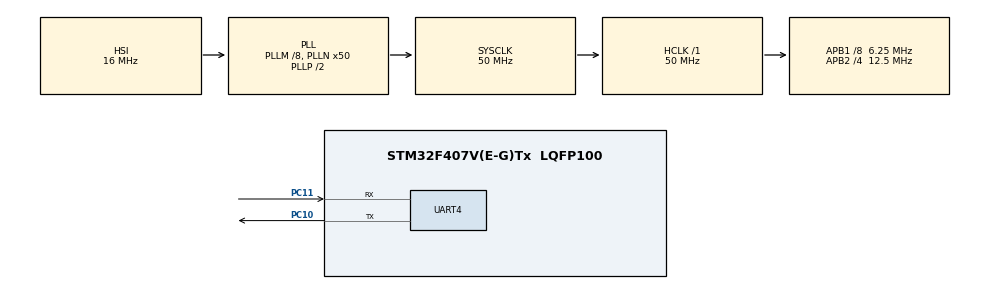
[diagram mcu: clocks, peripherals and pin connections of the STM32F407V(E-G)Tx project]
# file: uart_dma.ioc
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Dma.Request0=UART4_RX
Dma.Request1=UART4_TX
Dma.UART4_RX.0.Direction=DMA_PERIPH_TO_MEMORY
Dma.UART4_RX.0.FIFOMode=DMA_FIFOMODE_DISABLE
Dma.UART4_RX.0.Instance=DMA1_Stream2
Dma.UART4_RX.0.MemDataAlignment=DMA_MDATAALIGN_BYTE
Dma.UART4_RX.0.MemInc=DMA_MINC_ENABLE
Dma.UART4_RX.0.Mode=DMA_CIRCULAR
Dma.UART4_RX.0.PeriphDataAlignment=DMA_PDATAALIGN_BYTE
Dma.UART4_RX.0.PeriphInc=DMA_PINC_DISABLE
Dma.UART4_RX.0.Priority=DMA_PRIORITY_LOW
Dma.UART4_TX.1.Direction=DMA_MEMORY_TO_PERIPH
Dma.UART4_TX.1.FIFOMode=DMA_FIFOMODE_DISABLE
Dma.UART4_TX.1.Instance=DMA1_Stream4
Dma.UART4_TX.1.MemDataAlignment=DMA_MDATAALIGN_BYTE
Dma.UART4_TX.1.MemInc=DMA_MINC_ENABLE
Dma.UART4_TX.1.Mode=DMA_NORMAL
Dma.UART4_TX.1.PeriphDataAlignment=DMA_PDATAALIGN_BYTE
Dma.UART4_TX.1.PeriphInc=DMA_PINC_DISABLE
Dma.UART4_TX.1.Priority=DMA_PRIORITY_LOW
Mcu.Family=STM32F4
Mcu.Name=STM32F407V(E-G)Tx
Mcu.Package=LQFP100
NVIC.DMA1_Stream2_IRQn=true\:0\:0\:false\:false\:true\:false\:true
NVIC.DMA1_Stream4_IRQn=true\:0\:0\:false\:false\:true\:false\:true
NVIC.PriorityGroup=NVIC_PRIORITYGROUP_0
NVIC.UART4_IRQn=true\:0\:0\:false\:false\:true\:true\:true
PC10.Mode=Asynchronous
PC10.Signal=UART4_TX
PC11.Mode=Asynchronous
PC11.Signal=UART4_RX
ProjectManager.HeapSize=0x200
ProjectManager.StackSize=0x400
ProjectManager.TargetToolchain=STM32CubeIDE
RCC.48MHZClocksFreq_Value=14285714.285714285
RCC.AHBFreq_Value=50000000
RCC.APB1CLKDivider=RCC_HCLK_DIV8
RCC.APB1Freq_Value=6250000
RCC.APB1TimFreq_Value=12500000
RCC.APB2CLKDivider=RCC_HCLK_DIV4
RCC.APB2Freq_Value=12500000
RCC.APB2TimFreq_Value=25000000
RCC.CortexFreq_Value=50000000
RCC.HCLKFreq_Value=50000000
RCC.HSE_VALUE=8000000
RCC.HSI_VALUE=16000000
RCC.LSE_VALUE=32768
RCC.PLLM=8
RCC.PLLN=50
RCC.PLLQ=7
RCC.SYSCLKFreq_VALUE=50000000
RCC.SYSCLKSource=RCC_SYSCLKSOURCE_PLLCLK
RCC.VCOOutputFreq_Value=100000000
UART4.VirtualMode=Asynchronous
board=STM32F407G-DISC1

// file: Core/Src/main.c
/* USER CODE BEGIN Header */
/**
  ******************************************************************************
  * @file           : main.c
  * @brief          : Main program body
  ******************************************************************************
  * @attention
  *
  * <h2><center>&copy; Copyright (c) 2020 STMicroelectronics.
  * All rights reserved.</center></h2>
  *
  * This software component is licensed by ST under Ultimate Liberty license
  * SLA0044, the "License"; You may not use this file except in compliance with
  * the License. You may obtain a copy of the License at:
  *                             www.st.com/SLA0044
  *
  ******************************************************************************
  */
/* USER CODE END Header */

#include "main.h"

/* USER CODE BEGIN Includes */
#include <string.h>
#include <stdint.h>
/* USER CODE END Includes */

/* USER CODE BEGIN PD */
struct Buffer
{
    uint8_t front;
    uint8_t rear;
    uint8_t *arr;
};
//struct Buffer buffDMA;
struct Buffer buffUSR;

void buffer_init(struct Buffer *buff, uint8_t *buff_name);
//void buffer_add(struct Buffer *buff, uint8_t data);
//uint8_t buffer_get(struct Buffer *buff);
//uint8_t buffer_space(struct Buffer *buff);

/* USER CODE END PD */

/* USER CODE BEGIN PM */
//Size of buffer - DMA
#define DMA_BUFF_SIZE 10
//Size of buffer - USER
#define USR_BUFF_SIZE 50
/*
//Circular buffer EMPTY condition
#define BUFF_EMPTY  0
//Circular buffer FULL condition
#define BUFF_FULL   1
//Circular buffer NOT FULL condition
#define BUFF_NOT_FULL   2
*/

/* USER CODE END PM */

UART_HandleTypeDef huart4;
DMA_HandleTypeDef hdma_uart4_rx;
DMA_HandleTypeDef hdma_uart4_tx;

/* USER CODE BEGIN PV */
void delay(void);
/* USER CODE END PV */

void SystemClock_Config(void);
static void MX_GPIO_Init(void);
static void MX_DMA_Init(void);
static void MX_UART4_Init(void);

/* USER CODE BEGIN 0 */
uint8_t dma_buf[DMA_BUFF_SIZE];
uint8_t usr_buf[USR_BUFF_SIZE];	//circular buffer
uint8_t status = 0;
uint8_t tx_count = 0;
uint8_t rx_count = 0;

uint8_t temp[2] = {'a', 'b'};
/* USER CODE END 0 */

int main(void)
{

  /* MCU Configuration--------------------------------------------------------*/

  /* Reset of all peripherals, Initializes the Flash interface and the Systick. */
  HAL_Init();

  /* USER CODE BEGIN Init */
  //buffer_init(&buffDMA, dma_buf);
  buffer_init(&buffUSR, usr_buf);
  /* USER CODE END Init */

  /* Configure the system clock */
  SystemClock_Config();

  /* Initialize all configured peripherals */
  MX_GPIO_Init();
  MX_DMA_Init();
  MX_UART4_Init();
  /* USER CODE BEGIN 2 */
  HAL_UART_Receive_DMA(&huart4, dma_buf, DMA_BUFF_SIZE);
  /* USER CODE END 2 */

  /* Infinite loop */
  /* USER CODE BEGIN WHILE */
  while(1)
  {
	  if(status == 1)
	  {
		  status = 0;
		  HAL_UART_Transmit_DMA(&huart4, dma_buf, DMA_BUFF_SIZE);
	  }
    /* USER CODE END WHILE */

    /* USER CODE BEGIN 3 */
	//HAL_UART_Transmit_DMA(&huart4, temp, 2);
  }
  /* USER CODE END 3 */
}

void SystemClock_Config(void)
{
  RCC_OscInitTypeDef RCC_OscInitStruct = {0};
  RCC_ClkInitTypeDef RCC_ClkInitStruct = {0};

  /** Configure the main internal regulator output voltage
  */
  __HAL_RCC_PWR_CLK_ENABLE();
  __HAL_PWR_VOLTAGESCALING_CONFIG(PWR_REGULATOR_VOLTAGE_SCALE1);
  /** Initializes the CPU, AHB and APB busses clocks
  */
  RCC_OscInitStruct.OscillatorType = RCC_OSCILLATORTYPE_HSI;
  RCC_OscInitStruct.HSIState = RCC_HSI_ON;
  RCC_OscInitStruct.HSICalibrationValue = RCC_HSICALIBRATION_DEFAULT;
  RCC_OscInitStruct.PLL.PLLState = RCC_PLL_ON;
  RCC_OscInitStruct.PLL.PLLSource = RCC_PLLSOURCE_HSI;
  RCC_OscInitStruct.PLL.PLLM = 8;
  RCC_OscInitStruct.PLL.PLLN = 50;
  RCC_OscInitStruct.PLL.PLLP = RCC_PLLP_DIV2;
  RCC_OscInitStruct.PLL.PLLQ = 7;
  if (HAL_RCC_OscConfig(&RCC_OscInitStruct) != HAL_OK)
  {
    Error_Handler();
  }
  /** Initializes the CPU, AHB and APB busses clocks
  */
  RCC_ClkInitStruct.ClockType = RCC_CLOCKTYPE_HCLK|RCC_CLOCKTYPE_SYSCLK
                              |RCC_CLOCKTYPE_PCLK1|RCC_CLOCKTYPE_PCLK2;
  RCC_ClkInitStruct.SYSCLKSource = RCC_SYSCLKSOURCE_PLLCLK;
  RCC_ClkInitStruct.AHBCLKDivider = RCC_SYSCLK_DIV1;
  RCC_ClkInitStruct.APB1CLKDivider = RCC_HCLK_DIV8;
  RCC_ClkInitStruct.APB2CLKDivider = RCC_HCLK_DIV4;

  if (HAL_RCC_ClockConfig(&RCC_ClkInitStruct, FLASH_LATENCY_1) != HAL_OK)
  {
    Error_Handler();
  }
}

static void MX_UART4_Init(void)
{

  huart4.Instance = UART4;
  huart4.Init.BaudRate = 115200;
  huart4.Init.WordLength = UART_WORDLENGTH_8B;
  huart4.Init.StopBits = UART_STOPBITS_1;
  huart4.Init.Parity = UART_PARITY_NONE;
  huart4.Init.Mode = UART_MODE_TX_RX;
  huart4.Init.HwFlowCtl = UART_HWCONTROL_NONE;
  huart4.Init.OverSampling = UART_OVERSAMPLING_16;
  if (HAL_UART_Init(&huart4) != HAL_OK)
  {
    Error_Handler();
  }

}

static void MX_DMA_Init(void)
{

  /* DMA controller clock enable */
  __HAL_RCC_DMA1_CLK_ENABLE();

  /* DMA interrupt init */
  /* DMA1_Stream2_IRQn interrupt configuration */
  HAL_NVIC_SetPriority(DMA1_Stream2_IRQn, 0, 0);
  HAL_NVIC_EnableIRQ(DMA1_Stream2_IRQn);
  /* DMA1_Stream4_IRQn interrupt configuration */
  HAL_NVIC_SetPriority(DMA1_Stream4_IRQn, 0, 0);
  HAL_NVIC_EnableIRQ(DMA1_Stream4_IRQn);

}

static void MX_GPIO_Init(void)
{

  /* GPIO Ports Clock Enable */
  __HAL_RCC_GPIOC_CLK_ENABLE();

}

/* USER CODE BEGIN 4 */
void buffer_init(struct Buffer *buff, uint8_t *buff_name)
{
    buff->front = 0;
    buff->rear = 0;
    buff->arr = buff_name;
}

void delay(void)
{
	for(int j=0; j<500; j++);
}

//UART handling mechanism
void HAL_UART_RxCpltCallback(UART_HandleTypeDef *huart)
{
  /* Prevent unused argument(s) compilation warning */
  UNUSED(huart);
  /* NOTE: This function should not be modified, when the callback is needed,
           the HAL_UART_RxCpltCallback could be implemented in the user file
   */
  memcpy(usr_buf + buffUSR.rear, dma_buf, DMA_BUFF_SIZE);
  buffUSR.rear = (buffUSR.rear + DMA_BUFF_SIZE) % USR_BUFF_SIZE;
  status = 1;
  rx_count++;
}

void HAL_UART_TxCpltCallback(UART_HandleTypeDef *huart)
{
  /* Prevent unused argument(s) compilation warning */
  UNUSED(huart);
  /* NOTE: This function should not be modified, when the callback is needed,
           the HAL_UART_TxCpltCallback could be implemented in the user file
   */

  buffUSR.front = (buffUSR.front + DMA_BUFF_SIZE) % USR_BUFF_SIZE;
  tx_count++;
}

/* USER CODE END 4 */

void Error_Handler(void)
{
}

/************************ (C) COPYRIGHT STMicroelectronics *****END OF FILE****/
